# ing916 register map
Vendor: INGChips; Series: ing916xx; File version: 522
CPU: CM4 r0p1, little endian, MPU, FPU, VTOR, 5 interrupt priority bits
Registers are 32-bit, read-write, reset 0x0 unless marked. A register's access mark holds for its fields unless they carry their own. Offsets are from the block's base; [hi:lo] are bit positions; {n}, {i} and the like mark numbered series.

## I2C0
Base 0x40013000
Same registers: I2C1 0x40014000
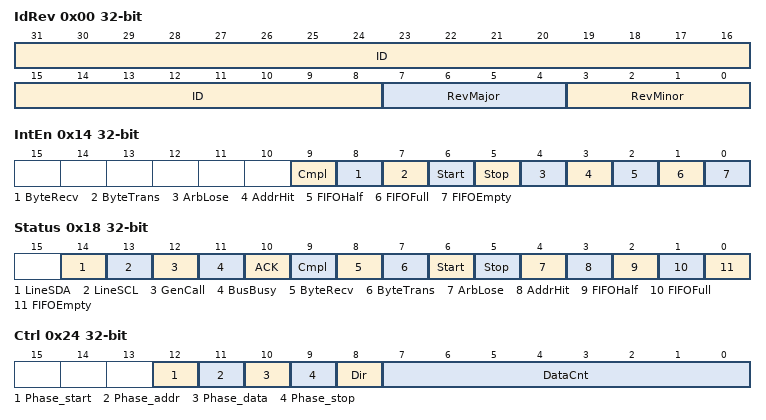
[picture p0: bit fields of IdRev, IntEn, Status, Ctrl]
0x00 IdRev — reg description:
  [31:8] ID — reg description:
  [7:4] RevMajor — reg description:
  [3:0] RevMinor — reg description:
0x10 Cfg — reg description:
  [1:0] FIFOSize
0x14 IntEn — reg description:
  [9] Cmpl — reg description:
  [8] ByteRecv — reg description:
  [7] ByteTrans — reg description:
  [6] Start — reg description:
  [5] Stop — reg description:
  [4] ArbLose — reg description:
  [3] AddrHit — reg description:
  [2] FIFOHalf — reg description:
  [1] FIFOFull — reg description:
  [0] FIFOEmpty — reg description:
0x18 Status — reg description:
  [14] LineSDA — reg description:
  [13] LineSCL — reg description:
  [12] GenCall — reg description:
  [11] BusBusy — reg description:
  [10] ACK — reg description:
  [9] Cmpl — reg description:
  [8] ByteRecv — reg description:
  [7] ByteTrans — reg description:
  [6] Start — reg description:
  [5] Stop — reg description:
  [4] ArbLose — reg description:
  [3] AddrHit — reg description:
  [2] FIFOHalf — reg description:
  [1] FIFOFull — reg description:
  [0] FIFOEmpty — reg description:
0x1C Addr — reg description:
  [9:0] Addr
0x20 Data — reg description:
  [7:0] Data
0x24 Ctrl — reg description:
  [12] Phase_start — reg description:
  [11] Phase_addr — reg description:
  [10] Phase_data — reg description:
  [9] Phase_stop — reg description:
  [8] Dir — reg description:
  [7:0] DataCnt — reg description:
0x28 Cmd — reg description:
  [2:0] CMD
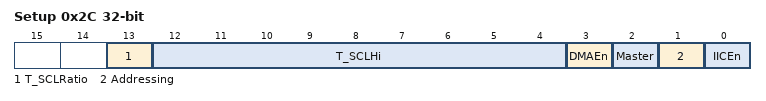
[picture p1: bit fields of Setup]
0x2C Setup — reg description:
  [13] T_SCLRatio — reg description:
  [12:4] T_SCLHi — reg description:
  [3] DMAEn — reg description:
  [2] Master — reg description:
  [1] Addressing — reg description:
  [0] IICEn — reg description:
0x30 TPM — reg description:
  [4:0] TPM

## GPIO0
Base 0x40015000
Same registers: GPIO1 0x40016000
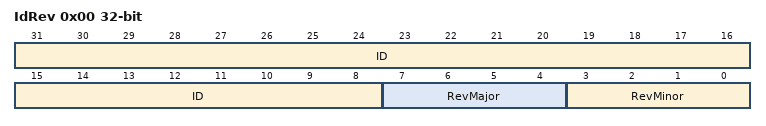
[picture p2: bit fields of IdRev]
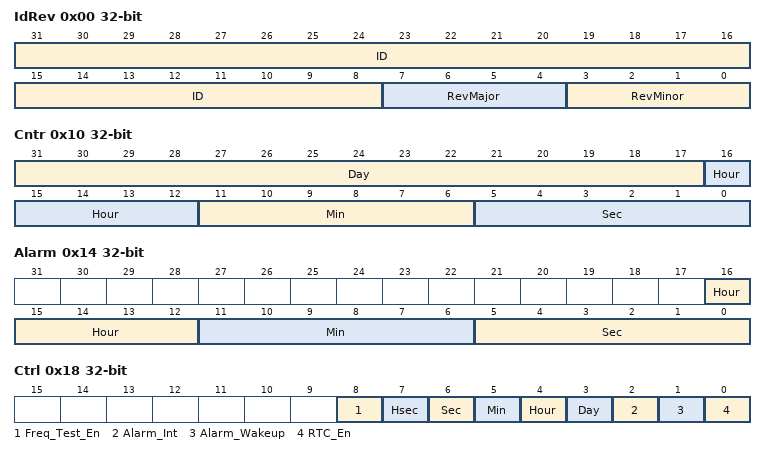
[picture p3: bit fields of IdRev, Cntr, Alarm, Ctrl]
0x00 IdRev — reg description:
  [31:8] ID — reg description:
  [7:4] RevMajor — reg description:
  [3:0] RevMinor — reg description:
0x10 Cfg — reg description:
  [5:0] ChannelNum
0x20 DataIn — reg description:
  [20:0] DataIn
0x24 DataOut — reg description:
  [20:0] DataOut
0x28 ChannelDir — reg description:
  [20:0] ChannelDir
0x2C DoutClear — reg description:
  [20:0] DoutClear
0x30 DoutSet — reg description:
  [20:0] DoutSet
0x34 IOIE — reg description:
  [20:0] gpio_ie_reg
0x50 IntrEn — reg description:
  [20:0] IntEn
{0x54+4i} IntrMode{i} (i=0..2) — reg description:
  [2:0] Ch{8i}IntrM
0x64 IntrStatus — reg description:
  [20:0] IntrStatus
0x70 DeBounceEn — reg description:
  [20:0] DeBounceEn
0x74 DeBounceCtrl — reg description:
  [7:0] DBPreScale

## RTC
Base 0x40101000
0x00 IdRev — reg description:
  [31:8] ID — reg description:
  [7:4] RevMajor — reg description:
  [3:0] RevMinor — reg description:
0x10 Cntr — reg description:
  [31:17] Day — reg description:
  [16:12] Hour — reg description:
  [11:6] Min — reg description:
  [5:0] Sec — reg description:
0x14 Alarm — reg description:
  [16:12] Hour — reg description:
  [11:6] Min — reg description:
  [5:0] Sec — reg description:
0x18 Ctrl — reg description:
  [8] Freq_Test_En — reg description:
  [7] Hsec — reg description:
  [6] Sec — reg description:
  [5] Min — reg description:
  [4] Hour — reg description:
  [3] Day — reg description:
  [2] Alarm_Int — reg description:
  [1] Alarm_Wakeup — reg description:
  [0] RTC_En — reg description:
0x1C St — reg description:
0x20 Trim — reg description:
  [4:0] Sec_Trim
0x24 SEC_CFG — reg description:
  [13:0] sec_cnt_cfg

## AHBAES
Base 0x40130000
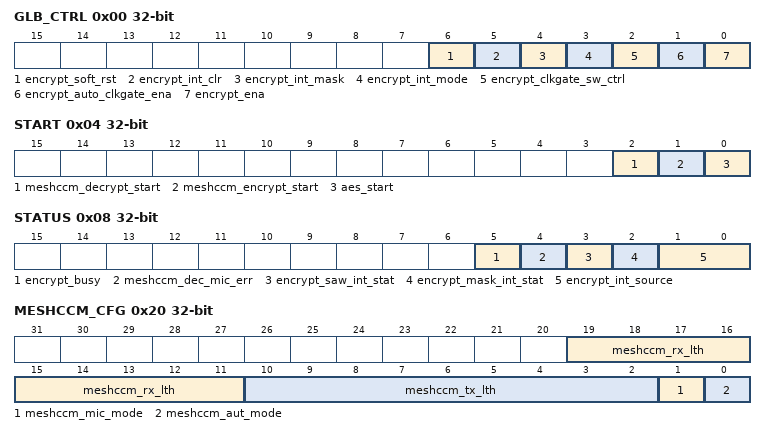
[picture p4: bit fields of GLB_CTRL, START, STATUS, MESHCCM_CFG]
0x00 GLB_CTRL — reg description:
  [6] encrypt_soft_rst — reg description:
  [5] encrypt_int_clr — reg description:
  [4] encrypt_int_mask — reg description:
  [3] encrypt_int_mode — reg description:
  [2] encrypt_clkgate_sw_ctrl — reg description:
  [1] encrypt_auto_clkgate_ena — reg description:
  [0] encrypt_ena — reg description:
0x04 START — reg description:
  [2] meshccm_decrypt_start — reg description:
  [1] meshccm_encrypt_start — reg description:
  [0] aes_start — reg description:
0x08 STATUS — reg description:
  [5] encrypt_busy — reg description:
  [4] meshccm_dec_mic_err — reg description:
  [3] encrypt_saw_int_stat — reg description:
  [2] encrypt_mask_int_stat — reg description:
  [1:0] encrypt_int_source — reg description:
0x0C AES_LOC — reg description:
  [9:0] aes_loc
{0x10+4i} KEY{i} (i=0..3) — reg description:
0x20 MESHCCM_CFG — reg description:
  [19:11] meshccm_rx_lth — reg description:
  [10:2] meshccm_tx_lth — reg description:
  [1] meshccm_mic_mode — reg description:
  [0] meshccm_aut_mode — reg description:
0x24 MESHCCM_LOC — reg description:
  [9:0] meshccm_ptr
{0x28+4i} MESHCCM_AUT_DATA{i} (i=0..3) — reg description:
{0x38+4i} MESHCCM_NONCE{i} (i=0..2) — reg description:
0x44 MESHCCM_NONCE3 — reg description:
  [7:0] meshccm_nonce3
0x48 MESHCCM_DECRYPT_MIC — reg description:
0x4C MESHCCM_ENCRYPT_MIC — reg description:
